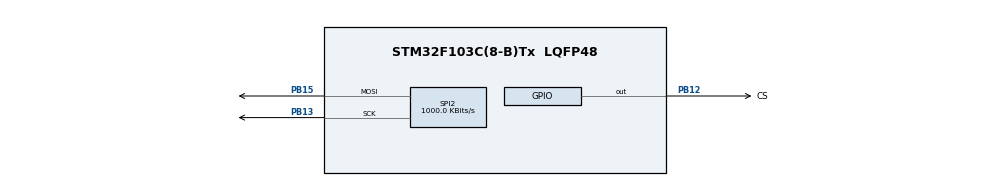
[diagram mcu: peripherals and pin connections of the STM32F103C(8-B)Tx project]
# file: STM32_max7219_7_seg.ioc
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Mcu.Family=STM32F1
Mcu.Name=STM32F103C(8-B)Tx
Mcu.Package=LQFP48
NVIC.PriorityGroup=NVIC_PRIORITYGROUP_4
PA13.Mode=Serial_Wire
PA13.Signal=SYS_JTMS-SWDIO
PA14.Mode=Serial_Wire
PA14.Signal=SYS_JTCK-SWCLK
PB12.GPIO_Label=CS
PB12.Signal=GPIO_Output
PB13.Mode=TX_Only_Simplex_Unidirect_Master
PB13.Signal=SPI2_SCK
PB15.Mode=TX_Only_Simplex_Unidirect_Master
PB15.Signal=SPI2_MOSI
ProjectManager.HeapSize=0x200
ProjectManager.StackSize=0x400
ProjectManager.TargetToolchain=Makefile
RCC.APB1CLKDivider=RCC_HCLK_DIV4
RCC.APB1Freq_Value=2000000
RCC.APB1TimFreq_Value=4000000
RCC.APB2Freq_Value=8000000
RCC.APB2TimFreq_Value=8000000
SPI2.CalculateBaudRate=1000.0 KBits/s
SPI2.Direction=SPI_DIRECTION_2LINES
SPI2.Mode=SPI_MODE_MASTER
SPI2.VirtualType=VM_MASTER
board=STM32_max7219_7_seg

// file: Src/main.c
/**
  ******************************************************************************
  * File Name          : main.c
  * Description        : Main program body
  ******************************************************************************
  ** This notice applies to any and all portions of this file
  * that are not between comment pairs USER CODE BEGIN and
  * USER CODE END. Other portions of this file, whether
  * inserted by the user or by software development tools
  * are owned by their respective copyright owners.
  *
  * COPYRIGHT(c) 2018 STMicroelectronics
  *
  * Redistribution and use in source and binary forms, with or without modification,
  * are permitted provided that the following conditions are met:
  *   1. Redistributions of source code must retain the above copyright notice,
  *      this list of conditions and the following disclaimer.
  *   2. Redistributions in binary form must reproduce the above copyright notice,
  *      this list of conditions and the following disclaimer in the documentation
  *      and/or other materials provided with the distribution.
  *   3. Neither the name of STMicroelectronics nor the names of its contributors
  *      may be used to endorse or promote products derived from this software
  *      without specific prior written permission.
  *
  * THIS SOFTWARE IS PROVIDED BY THE COPYRIGHT HOLDERS AND CONTRIBUTORS "AS IS"
  * AND ANY EXPRESS OR IMPLIED WARRANTIES, INCLUDING, BUT NOT LIMITED TO, THE
  * IMPLIED WARRANTIES OF MERCHANTABILITY AND FITNESS FOR A PARTICULAR PURPOSE ARE
  * DISCLAIMED. IN NO EVENT SHALL THE COPYRIGHT HOLDER OR CONTRIBUTORS BE LIABLE
  * FOR ANY DIRECT, INDIRECT, INCIDENTAL, SPECIAL, EXEMPLARY, OR CONSEQUENTIAL
  * DAMAGES (INCLUDING, BUT NOT LIMITED TO, PROCUREMENT OF SUBSTITUTE GOODS OR
  * SERVICES; LOSS OF USE, DATA, OR PROFITS; OR BUSINESS INTERRUPTION) HOWEVER
  * CAUSED AND ON ANY THEORY OF LIABILITY, WHETHER IN CONTRACT, STRICT LIABILITY,
  * OR TORT (INCLUDING NEGLIGENCE OR OTHERWISE) ARISING IN ANY WAY OUT OF THE USE
  * OF THIS SOFTWARE, EVEN IF ADVISED OF THE POSSIBILITY OF SUCH DAMAGE.
  *
  ******************************************************************************
  */
#include "main.h"
#include "stm32f1xx_hal.h"

/* USER CODE BEGIN Includes */
#include "max7219.h"
/* USER CODE END Includes */

SPI_HandleTypeDef hspi2;

/* USER CODE BEGIN PV */
/* Private variables ---------------------------------------------------------*/
/* USER CODE END PV */

void SystemClock_Config(void);
static void MX_GPIO_Init(void);
static void MX_SPI2_Init(void);

/* USER CODE BEGIN PFP */
/* Private function prototypes -----------------------------------------------*/

/* USER CODE END PFP */

int main(void)
{

  /* USER CODE BEGIN 1 */
	uint32_t i=0;
  /* USER CODE END 1 */

  /* MCU Configuration----------------------------------------------------------*/

  /* Reset of all peripherals, Initializes the Flash interface and the Systick. */
  HAL_Init();

  /* Configure the system clock */
  SystemClock_Config();

  /* Initialize all configured peripherals */
  MX_GPIO_Init();
  MX_SPI2_Init();

  /* USER CODE BEGIN 2 */
  HAL_Delay(200);
  Init_7219();
  Send_7219(1,0x01);
  Send_7219(2,0x02);
  Send_7219(3,0x03);
  Send_7219(4,0x04);
  Send_7219(5,0x05);
  Send_7219(6,0x06);
  Send_7219(7,0x07);
  Send_7219(8,0x08);
  HAL_Delay(2000);
  Clear_7219();
  Number_7219(-4356);
  HAL_Delay(2000);
  Clear_7219();
  /* USER CODE END 2 */

  /* Infinite loop */
  /* USER CODE BEGIN WHILE */
  while (1)
  {
    Number_7219(i);
    HAL_Delay(200);
    i++;
  /* USER CODE END WHILE */

  }

}

/** System Clock Configuration
*/
void SystemClock_Config(void)
{

  RCC_OscInitTypeDef RCC_OscInitStruct;
  RCC_ClkInitTypeDef RCC_ClkInitStruct;

    /**Initializes the CPU, AHB and APB busses clocks
    */
  RCC_OscInitStruct.OscillatorType = RCC_OSCILLATORTYPE_HSI;
  RCC_OscInitStruct.HSIState = RCC_HSI_ON;
  RCC_OscInitStruct.HSICalibrationValue = 16;
  RCC_OscInitStruct.PLL.PLLState = RCC_PLL_NONE;
  if (HAL_RCC_OscConfig(&RCC_OscInitStruct) != HAL_OK)
  {
    _Error_Handler(__FILE__, __LINE__);
  }

    /**Initializes the CPU, AHB and APB busses clocks
    */
  RCC_ClkInitStruct.ClockType = RCC_CLOCKTYPE_HCLK|RCC_CLOCKTYPE_SYSCLK
                              |RCC_CLOCKTYPE_PCLK1|RCC_CLOCKTYPE_PCLK2;
  RCC_ClkInitStruct.SYSCLKSource = RCC_SYSCLKSOURCE_HSI;
  RCC_ClkInitStruct.AHBCLKDivider = RCC_SYSCLK_DIV1;
  RCC_ClkInitStruct.APB1CLKDivider = RCC_HCLK_DIV4;
  RCC_ClkInitStruct.APB2CLKDivider = RCC_HCLK_DIV1;

  if (HAL_RCC_ClockConfig(&RCC_ClkInitStruct, FLASH_LATENCY_0) != HAL_OK)
  {
    _Error_Handler(__FILE__, __LINE__);
  }

    /**Configure the Systick interrupt time
    */
  HAL_SYSTICK_Config(HAL_RCC_GetHCLKFreq()/1000);

    /**Configure the Systick
    */
  HAL_SYSTICK_CLKSourceConfig(SYSTICK_CLKSOURCE_HCLK);

  /* SysTick_IRQn interrupt configuration */
  HAL_NVIC_SetPriority(SysTick_IRQn, 0, 0);
}

/* SPI2 init function */
static void MX_SPI2_Init(void)
{

  hspi2.Instance = SPI2;
  hspi2.Init.Mode = SPI_MODE_MASTER;
  hspi2.Init.Direction = SPI_DIRECTION_2LINES;
  hspi2.Init.DataSize = SPI_DATASIZE_8BIT;
  hspi2.Init.CLKPolarity = SPI_POLARITY_LOW;
  hspi2.Init.CLKPhase = SPI_PHASE_1EDGE;
  hspi2.Init.NSS = SPI_NSS_SOFT;
  hspi2.Init.BaudRatePrescaler = SPI_BAUDRATEPRESCALER_2;
  hspi2.Init.FirstBit = SPI_FIRSTBIT_MSB;
  hspi2.Init.TIMode = SPI_TIMODE_DISABLE;
  hspi2.Init.CRCCalculation = SPI_CRCCALCULATION_DISABLE;
  hspi2.Init.CRCPolynomial = 10;
  if (HAL_SPI_Init(&hspi2) != HAL_OK)
  {
    _Error_Handler(__FILE__, __LINE__);
  }

}

/** Configure pins as
        * Analog
        * Input
        * Output
        * EVENT_OUT
        * EXTI
*/
static void MX_GPIO_Init(void)
{

  GPIO_InitTypeDef GPIO_InitStruct;

  /* GPIO Ports Clock Enable */
  __HAL_RCC_GPIOB_CLK_ENABLE();
  __HAL_RCC_GPIOA_CLK_ENABLE();

  /*Configure GPIO pin Output Level */
  HAL_GPIO_WritePin(CS_GPIO_Port, CS_Pin, GPIO_PIN_RESET);

  /*Configure GPIO pin : CS_Pin */
  GPIO_InitStruct.Pin = CS_Pin;
  GPIO_InitStruct.Mode = GPIO_MODE_OUTPUT_PP;
  GPIO_InitStruct.Speed = GPIO_SPEED_FREQ_LOW;
  HAL_GPIO_Init(CS_GPIO_Port, &GPIO_InitStruct);

}

void _Error_Handler(char * file, int line)
{
  while(1)
  {
  }
}

/************************ (C) COPYRIGHT STMicroelectronics *****END OF FILE****/
